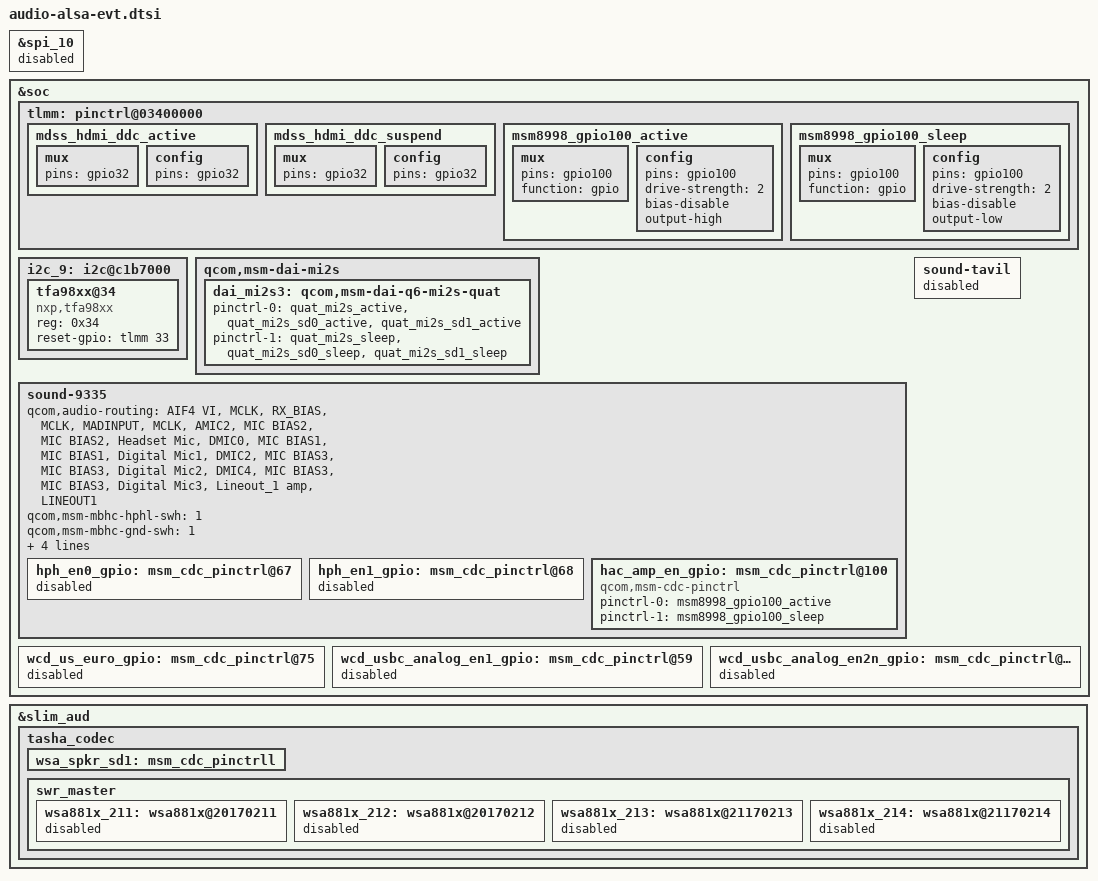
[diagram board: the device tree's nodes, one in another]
&spi_10 {
	status = "disabled";
};

&soc {
	tlmm: pinctrl@03400000 {
		mdss_hdmi_ddc_active: mdss_hdmi_ddc_active {
			mux {
				pins = "gpio32";
			};

			config {
				pins = "gpio32";
			};
		};

		mdss_hdmi_ddc_suspend: mdss_hdmi_ddc_suspend {
			mux {
				pins = "gpio32";
			};

			config {
				pins = "gpio32";
			};
		};
		/* gpio 100 */ /* HAC_AMP_EN */
		msm8998_gpio100_active: msm8998_gpio100_active {
			mux {
				pins = "gpio100";
				function = "gpio";
			};
			config {
				pins = "gpio100";
				drive-strength = <2>;
				bias-disable;
				output-high;
			};
		};

		msm8998_gpio100_sleep: msm8998_gpio100_sleep {
			mux {
				pins = "gpio100";
				function = "gpio";
			};
			config {
				pins = "gpio100";
				drive-strength = <2>;
				bias-disable;
				output-low;
			};
		};

	};

	i2c_9: i2c@c1b7000 { /* BLSP2 QUP3 */
		status = "okay";
		tfa98xx@34 {
			compatible = "nxp,tfa98xx";
			reg = <0x34>;
			reset-gpio = <&tlmm 33 0>;
		};
	};

	qcom,msm-dai-mi2s {
		dai_mi2s3: qcom,msm-dai-q6-mi2s-quat {
			pinctrl-names = "default", "sleep";
			pinctrl-0 = <&quat_mi2s_active &quat_mi2s_sd0_active &quat_mi2s_sd1_active>;
			pinctrl-1 = <&quat_mi2s_sleep &quat_mi2s_sd0_sleep &quat_mi2s_sd1_sleep>;
		};
	};

	sound-9335 {
		qcom,audio-routing =
			"AIF4 VI", "MCLK",
			"RX_BIAS", "MCLK",
			"MADINPUT", "MCLK",
			"AMIC2", "MIC BIAS2",
			"MIC BIAS2", "Headset Mic",
			"DMIC0", "MIC BIAS1",
			"MIC BIAS1", "Digital Mic1",
			"DMIC2", "MIC BIAS3",
			"MIC BIAS3", "Digital Mic2",
			"DMIC4", "MIC BIAS3",
			"MIC BIAS3", "Digital Mic3",
			"Lineout_1 amp", "LINEOUT1";

		qcom,msm-mbhc-hphl-swh = <1>;
		qcom,msm-mbhc-gnd-swh = <1>;
		fih_acdb = "EVT";
		devmodel = "A1N";
		/delete-property/ qcom,us-euro-gpios;
		/delete-property/ qcom,hph-en0-gpio;
		/delete-property/ qcom,hph-en1-gpio;

		qcom,wsa-max-devs = <0>;
		/delete-property/ qcom,wsa-devs ;
		/delete-property/ qcom,wsa-aux-dev-prefix ;
		fih,hac-amp-en-gpio = <&hac_amp_en_gpio>;	/* HAC enable gpio */

		hph_en0_gpio: msm_cdc_pinctrl@67 {
			status = "disabled";
		};

		hph_en1_gpio: msm_cdc_pinctrl@68 {
			status = "disabled";
		};

		hac_amp_en_gpio: msm_cdc_pinctrl@100 {
			compatible = "qcom,msm-cdc-pinctrl";
			pinctrl-names = "aud_active", "aud_sleep";
			pinctrl-0 = <&msm8998_gpio100_active>;
			pinctrl-1 = <&msm8998_gpio100_sleep>;
		};
	};

	sound-tavil {
		status = "disabled";
	};

	wcd_us_euro_gpio: msm_cdc_pinctrl@75 {
		status = "disabled";
	};

	wcd_usbc_analog_en1_gpio: msm_cdc_pinctrl@59 {
		status = "disabled";
	};

	wcd_usbc_analog_en2n_gpio: msm_cdc_pinctrl@60 {
		status = "disabled";
	};
};

&slim_aud {
	tasha_codec {
		wsa_spkr_sd1: msm_cdc_pinctrll {
			/delete-property/compatible;
			/delete-property/pinctrl-names;
			/delete-property/pinctrl-0;
			/delete-property/pinctrl-1;
		};

		swr_master {
			wsa881x_211: wsa881x@20170211 {
				status = "disabled";
			};

			wsa881x_212: wsa881x@20170212 {
				status = "disabled";
			};

			wsa881x_213: wsa881x@21170213 {
				status = "disabled";
			};

			wsa881x_214: wsa881x@21170214 {
				status = "disabled";
			};
		};
	};
};
